# PIC32MZ1025DAB176 register map
Vendor: Microchip
Registers are 32-bit, read-write, reset 0x0 unless marked. A register's access mark holds for its fields unless they carry their own. Addresses are absolute, and some are shared; only a register's first bit layout is shown; [hi:lo] are bit positions; {n}, {i} and the like mark numbered series.

## PMP
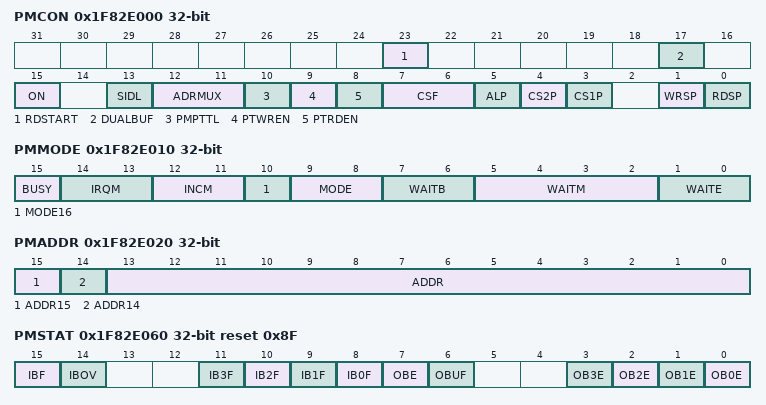
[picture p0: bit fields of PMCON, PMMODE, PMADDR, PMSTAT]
0x1F82E000 PMCON reset not defined — (power-on value --------x-----x-00000-0000000-00)
  [23] RDSTART, [17] DUALBUF, [15] ON, [13] SIDL, [12:11] ADRMUX, [10] PMPTTL, [9] PTWREN, [8] PTRDEN, [7:6] CSF, [5] ALP, [4] CS2P, [3] CS1P, [1] WRSP, [0] RDSP
0x1F82E010 PMMODE
  [15] BUSY, [14:13] IRQM, [12:11] INCM, [10] MODE16, [9:8] MODE, [7:6] WAITB, [5:2] WAITM, [1:0] WAITE
0x1F82E020 PMADDR reset not defined — (power-on value ----------------xxxxxxxxxxxxxxxx)
  [15] ADDR15, [14] ADDR14, [13:0] ADDR
0x1F82E030 PMDOUT reset not defined — (power-on value xxxxxxxxxxxxxxxxxxxxxxxxxxxxxxxx)
  [31:0] DATAOUT
0x1F82E040 PMDIN reset not defined — (power-on value xxxxxxxxxxxxxxxxxxxxxxxxxxxxxxxx)
  [31:0] DATAIN
0x1F82E050 PMAEN reset not defined — (power-on value --------xxxxxxxxxxxxxxxxxxxxxxxx)
  [23:0] PTEN
0x1F82E060 PMSTAT reset 0x8F
  [15] IBF ro, [14] IBOV, [n+8] IB{n}F ro (n=0..3), [7] OBE ro, [6] OBUF, [n] OB{n}E ro (n=0..3)
0x1F82E070 PMWADDR reset not defined — (power-on value --------xxxxxxxxxxxxxxxxxxxxxxxx)
  [23:0] WADDR
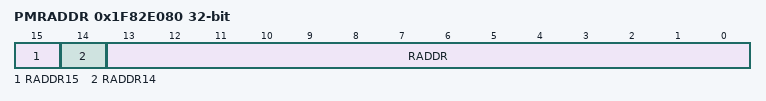
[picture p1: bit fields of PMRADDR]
0x1F82E080 PMRADDR reset not defined — (power-on value ----------------xxxxxxxxxxxxxxxx)
  [15] RADDR15, [14] RADDR14, [13:0] RADDR
0x1F82E090 PMRDIN reset not defined — (power-on value xxxxxxxxxxxxxxxxxxxxxxxxxxxxxxxx)
  [31:0] RDATAIN

## TMR1
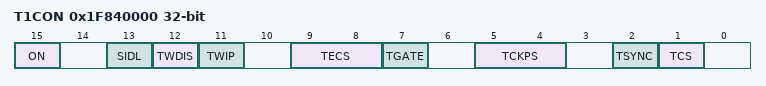
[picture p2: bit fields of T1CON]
0x1F840000 T1CON
  [15] ON, [13] SIDL, [12] TWDIS, [11] TWIP, [9:8] TECS, [7] TGATE, [5:4] TCKPS, [2] TSYNC, [1] TCS
0x1F840010 TMR1
0x1F840020 PR1 reset 0xFFFF

## TMR2
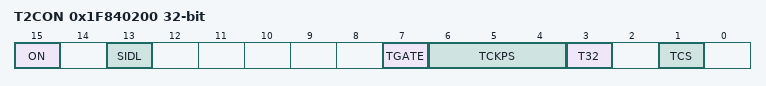
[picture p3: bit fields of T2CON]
0x1F840200 T2CON
  [15] ON, [13] SIDL, [7] TGATE, [6:4] TCKPS, [3] T32, [1] TCS
0x1F840210 TMR2
0x1F840220 PR2 reset 0xFFFF

## TMR3
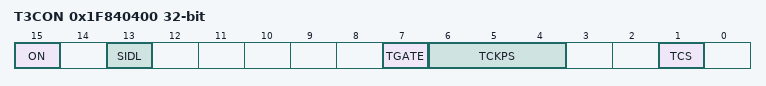
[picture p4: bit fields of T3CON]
0x1F840400 T3CON
  [15] ON, [13] SIDL, [7] TGATE, [6:4] TCKPS, [1] TCS
0x1F840410 TMR3
0x1F840420 PR3 reset 0xFFFF

## TMR4
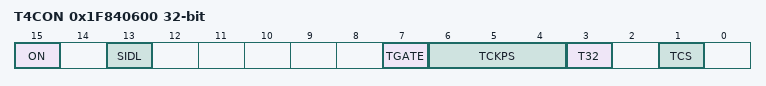
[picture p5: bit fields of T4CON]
0x1F840600 T4CON
  [15] ON, [13] SIDL, [7] TGATE, [6:4] TCKPS, [3] T32, [1] TCS
0x1F840610 TMR4
0x1F840620 PR4 reset 0xFFFF

## TMR5
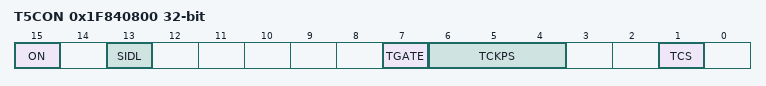
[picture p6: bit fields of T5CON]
0x1F840800 T5CON
  [15] ON, [13] SIDL, [7] TGATE, [6:4] TCKPS, [1] TCS
0x1F840810 TMR5
0x1F840820 PR5 reset 0xFFFF

## TMR6
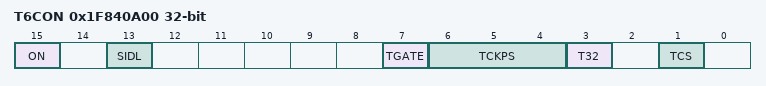
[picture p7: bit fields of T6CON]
0x1F840A00 T6CON
  [15] ON, [13] SIDL, [7] TGATE, [6:4] TCKPS, [3] T32, [1] TCS
0x1F840A10 TMR6
0x1F840A20 PR6 reset 0xFFFF

## TMR7
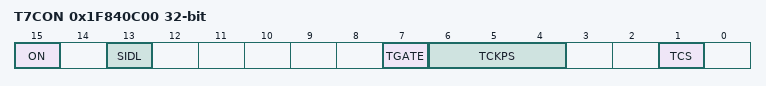
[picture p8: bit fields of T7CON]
0x1F840C00 T7CON
  [15] ON, [13] SIDL, [7] TGATE, [6:4] TCKPS, [1] TCS
0x1F840C10 TMR7
0x1F840C20 PR7 reset 0xFFFF

## TMR8
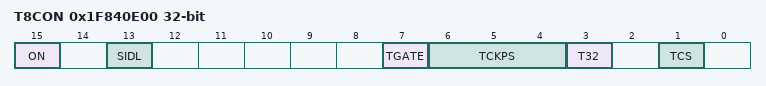
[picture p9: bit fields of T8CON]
0x1F840E00 T8CON
  [15] ON, [13] SIDL, [7] TGATE, [6:4] TCKPS, [3] T32, [1] TCS
0x1F840E10 TMR8
0x1F840E20 PR8 reset 0xFFFF

## TMR9
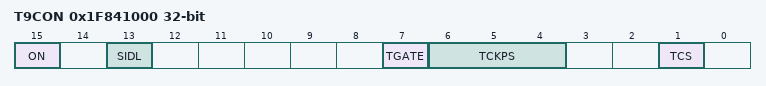
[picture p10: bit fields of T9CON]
0x1F841000 T9CON
  [15] ON, [13] SIDL, [7] TGATE, [6:4] TCKPS, [1] TCS
0x1F841010 TMR9
0x1F841020 PR9 reset 0xFFFF

## ICAP1
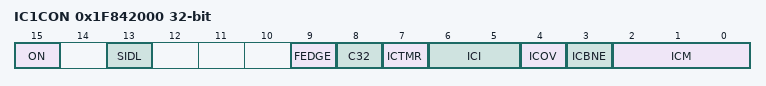
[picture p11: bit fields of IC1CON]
0x1F842000 IC1CON
  [15] ON, [13] SIDL, [9] FEDGE, [8] C32, [7] ICTMR, [6:5] ICI, [4] ICOV ro, [3] ICBNE ro, [2:0] ICM
0x1F842010 IC1BUF ro reset not defined — (power-on value xxxxxxxxxxxxxxxxxxxxxxxxxxxxxxxx)

## ICAP2
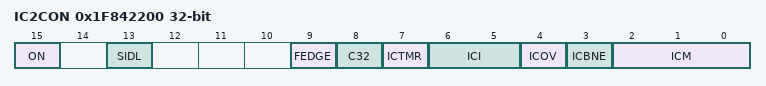
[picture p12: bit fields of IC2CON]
0x1F842200 IC2CON
  [15] ON, [13] SIDL, [9] FEDGE, [8] C32, [7] ICTMR, [6:5] ICI, [4] ICOV ro, [3] ICBNE ro, [2:0] ICM
0x1F842210 IC2BUF ro reset not defined — (power-on value xxxxxxxxxxxxxxxxxxxxxxxxxxxxxxxx)

## ICAP3
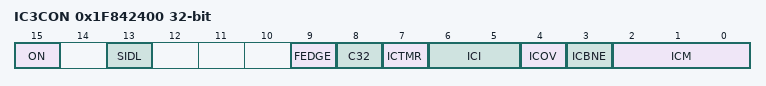
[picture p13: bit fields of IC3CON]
0x1F842400 IC3CON
  [15] ON, [13] SIDL, [9] FEDGE, [8] C32, [7] ICTMR, [6:5] ICI, [4] ICOV ro, [3] ICBNE ro, [2:0] ICM
0x1F842410 IC3BUF ro reset not defined — (power-on value xxxxxxxxxxxxxxxxxxxxxxxxxxxxxxxx)

## ICAP4
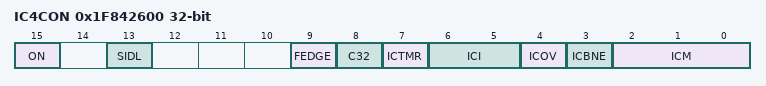
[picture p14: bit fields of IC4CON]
0x1F842600 IC4CON
  [15] ON, [13] SIDL, [9] FEDGE, [8] C32, [7] ICTMR, [6:5] ICI, [4] ICOV ro, [3] ICBNE ro, [2:0] ICM
0x1F842610 IC4BUF ro reset not defined — (power-on value xxxxxxxxxxxxxxxxxxxxxxxxxxxxxxxx)
